# MIMXRT685S_cm33 register map
Vendor: nxp.com; File version: 1.0
CPU: CM33 r2p0, little endian, MPU, FPU, VTOR, 3 interrupt priority bits
Registers are 32-bit, read-write, reset 0x0 unless marked. A register's access mark holds for its fields unless they carry their own. Offsets are from the block's base; [hi:lo] are bit positions; {n}, {i} and the like mark numbered series.

## POWERQUAD — LPC-Next0 Digital Signal Co-Processing companion to a Cortex-M v8M CPU core
Base 0x40150000
0x00 OUTBASE — Base address register for output region
  [31:0] outbase — Base address register for the output region
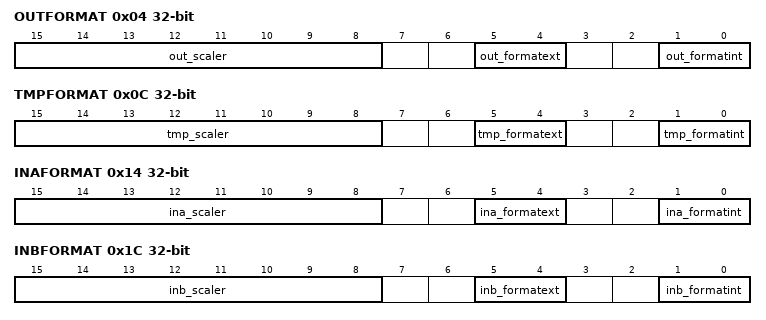
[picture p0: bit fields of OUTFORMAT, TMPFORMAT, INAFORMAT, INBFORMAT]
0x04 OUTFORMAT — Output format
  [15:8] out_scaler — Output Scaler value (for scaled 'q31' formats)
  [5:4] out_formatext — Output External format (00: q15; 01:q31; 10:float)
  [1:0] out_formatint — Output Internal format (00: q15; 01:q31; 10:float)
0x08 TMPBASE — Base address register for temp region
  [31:0] tmpbase — Base address register for the temporary region
0x0C TMPFORMAT — Temp format
  [15:8] tmp_scaler — Temp Scaler value (for scaled 'q31' formats)
  [5:4] tmp_formatext — Temp External format (00: q15; 01:q31; 10:float)
  [1:0] tmp_formatint — Temp Internal format (00: q15; 01:q31; 10:float)
0x10 INABASE — Base address register for input A region
  [31:0] inabase — Base address register for the input A region
0x14 INAFORMAT — Input A format
  [15:8] ina_scaler — Input A Scaler value (for scaled 'q31' formats)
  [5:4] ina_formatext — Input A External format (00: q15; 01:q31; 10:float)
  [1:0] ina_formatint — Input A Internal format (00: q15; 01:q31; 10:float)
0x18 INBBASE — Base address register for input B region
  [31:0] inbbase — Base address register for the input B region
0x1C INBFORMAT — Input B format
  [15:8] inb_scaler — Input B Scaler value (for scaled 'q31' formats)
  [5:4] inb_formatext — Input B External format (00: q15; 01:q31; 10:float)
  [1:0] inb_formatint — Input B Internal format (00: q15; 01:q31; 10:float)
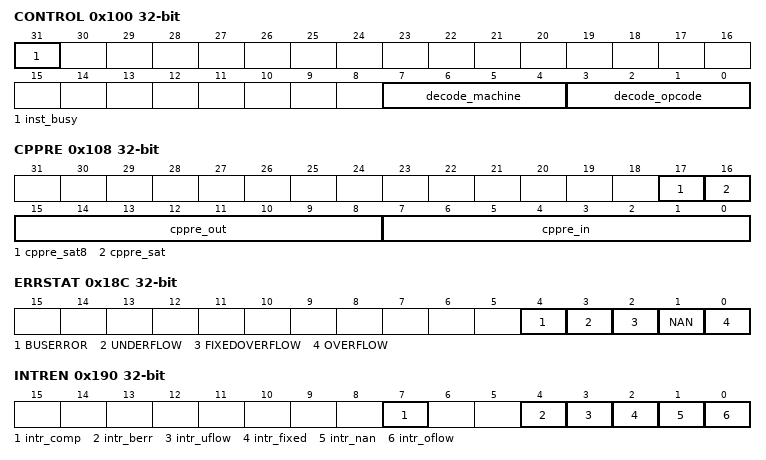
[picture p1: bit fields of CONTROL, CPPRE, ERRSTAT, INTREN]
0x100 CONTROL — PowerQuad Control register
  [31] inst_busy ro — Instruction busy signal when high indicates processing is on
  [7:4] decode_machine — 0 : Coprocessor , 1 : matrix , 2 : fft , 3 : fir , 4 : stat , 5 : cordic , 6 -15 : NA
  [3:0] decode_opcode — opcode specific to decode_machine
0x104 LENGTH
  [31:0] inst_length — Length register. When FIR : fir_xlength = inst_length[15:0] , fir_tlength = inst_len[31:16]. When MTX : rows_a = inst_length[4:0] , cols_a = inst_length[12:8] , cols_b = inst_length[20:16]
0x108 CPPRE — Pre-scale register
  [17] cppre_sat8 — 0 = 8bits, 1 = 16bits
  [16] cppre_sat — 1 : forces sub-32 bit saturation
  [15:8] cppre_out — co-processor fixed point output
  [7:0] cppre_in — co-processor scaling of input
0x10C MISC
  [31:0] inst_misc — Misc register. For Matrix : Used for scale factor
0x110 CURSORY
  [0] cursory — 1 : Enable cursory mode
0x180 CORDIC_X — Cordic input X register
  [31:0] cordic_x — Cordic input x
0x184 CORDIC_Y — Cordic input Y register
  [31:0] cordic_y — Cordic input y
0x188 CORDIC_Z — Cordic input Z register
  [31:0] cordic_z — Cordic input z
0x18C ERRSTAT — Read/Write register where error statuses are captured (sticky)
  [4] BUSERROR
  [3] UNDERFLOW
  [2] FIXEDOVERFLOW — fixed_pt_overflow
  [1] NAN
  [0] OVERFLOW
0x190 INTREN (reset mask 0x7F) — INTERRUPT enable register
  [7] intr_comp — 1: Enable interrupt on instruction completion
  [4] intr_berr — 1: Enable interrupt on AHBM Buss Error
  [3] intr_uflow — 1 : Enable interrupt on Subnormal truncation
  [2] intr_fixed — 1: Enable interrupt on Fixed point Overflow
  [1] intr_nan — 1 : Enable interrupt on Floating point NaN
  [0] intr_oflow — 1 : Enable interrupt on Floating point overflow
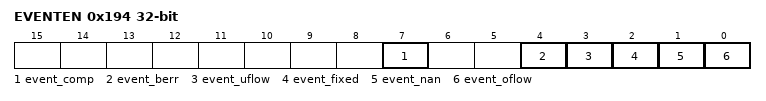
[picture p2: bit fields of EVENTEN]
0x194 EVENTEN — Event Enable register
  [7] event_comp — 1: Enable event trigger on instruction completion
  [4] event_berr — 1: Enable event trigger on AHBM Buss Error
  [3] event_uflow — 1 : Enable event trigger on Subnormal truncation
  [2] event_fixed — 1: Enable event trigger on Fixed point Overflow
  [1] event_nan — 1 : Enable event trigger on Floating point NaN
  [0] event_oflow — 1 : Enable event trigger on Floating point overflow
0x198 INTRSTAT — INTERRUPT STATUS register
  [0] intr_stat — Intr status ( 1 bit to indicate interrupt captured, 0 means no new interrupt), write any value will clear this bit
{0x200+4i} gpreg[{i}] (i=0..15) (reset mask 0x7CF73) — General purpose register bank N.
  [31:0] gpreg — General purpose register bank
{0x240+4i} compreg[{i}] (i=0..7) — Compute register bank
  [31:0] compreg
